# ATSAML22G18A register map
Vendor: Atmel Corporation; Series: SAML22; File version: A
CPU: CM0+ r0p1, little endian, MPU, no FPU, VTOR, 2 interrupt priority bits
Registers are 32-bit, read-write, reset 0x0 unless marked. A register's access mark holds for its fields unless they carry their own. Offsets are from the block's base; [hi:lo] are bit positions; {n}, {i} and the like mark numbered series; 'fields as' and 'values as' point back to an identical list.

## SLCD — Segment Liquid Crystal Display Controller
Base 0x42003C00; register names take the prefix SLCD_
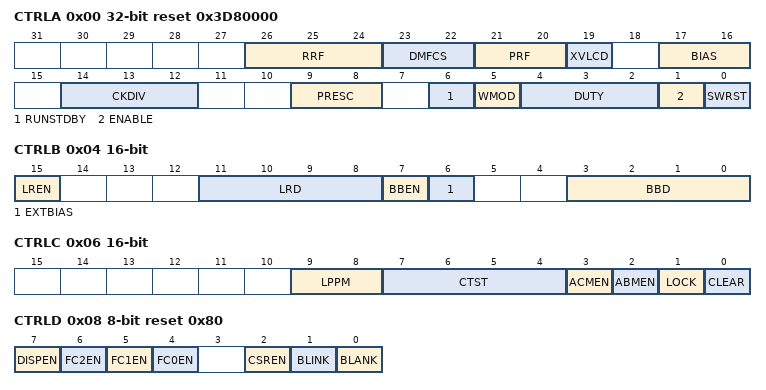
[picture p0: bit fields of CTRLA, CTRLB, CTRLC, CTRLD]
0x00 CTRLA reset 0x3D80000 — Control A
  [26:24] RRF — Reference Refresh Frequency
    0=RR2000 (2kHz); 1=RR1000 (1kHz); 2=RR500 (500Hz); 3=RR250 (250Hz); 4=RR125 (125Hz); 5=RR62 (62.5Hz)
  [23:22] DMFCS — Display Memory Update Frame Counter Selection
    0=FC0 (Frame Counter 0); 1=FC1 (Frame Counter 1); 2=FC2 (Frame Counter 2); 3=NFC (Frame Counter event to DMU is forced to 0)
  [21:20] PRF — Power Refresh Frequency
    0=PR2000 (2kHz); 1=PR1000 (1kHz); 2=PR500 (500Hz); 3=PR250 (250Hz)
  [19] XVLCD — External VLCD
  [17:16] BIAS — Bias Setting
    0=STATIC; 1=HALF (1/2 bias); 2=THIRD (1/3 bias); 3=FOURTH (1/4 bias)
  [14:12] CKDIV — Clock Divider
  [9:8] PRESC — Clock Prescaler
    0=16; 1=32; 2=64; 3=128
  [6] RUNSTDBY — Run in Standby
  [5] WMOD — Waveform Mode
    0=LP (Low Power Waveform Mode); 1=STD (Standard Waveform Mode)
  [4:2] DUTY — Duty Ratio
    0=STATIC (Static duty); 1=HALF (1/2 duty); 2=THIRD (1/3 duty); 3=FOURTH (1/4 duty); 4=SIXTH (1/6 duty); 5=EIGHT (1/8 duty)
  [1] ENABLE
  [0] SWRST — Software Reset
0x04 CTRLB 16-bit — Control B
  [15] LREN — Low Resistance Enable
  [11:8] LRD — Low Resistance Enable Duration
  [7] BBEN — Bias Buffer Enable
  [6] EXTBIAS — External Bias Capacitor
  [3:0] BBD — Bias Buffer Enable Duration
0x06 CTRLC 16-bit — Control C
  [9:8] LPPM — LCD Power Macro Power mode
    0=AUTO (LCD power automatically select regualation mode or pump mode); 1=STEPUP (LCD power use step-up pump loop only); 2=STEPDOWN (LCD power use step-down drop-out regulation loop only)
  [7:4] CTST — Contrast Adjustment
  [3] ACMEN — Automated Character Mapping Enable
  [2] ABMEN — Automated Bit Mapping Enable
  [1] LOCK — Lock Shadow Memory
  [0] CLEAR — Clear Display Memory
0x08 CTRLD 8-bit reset 0x80 — Control D
  [7] DISPEN — Display enable
  [6] FC2EN — Frame Counter 2 Enable
  [5] FC1EN — Frame Counter 1 Enable
  [4] FC0EN — Frame Counter 0 Enable
  [2] CSREN — Circular Shift Register Enable
  [1] BLINK — Blinking Enable
  [0] BLANK — Blank LCD
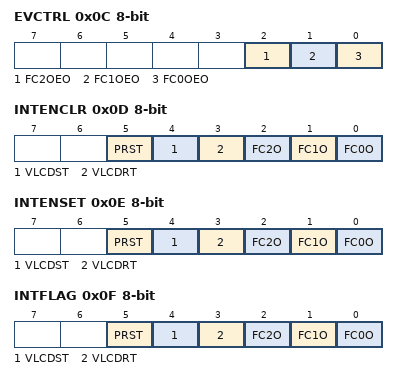
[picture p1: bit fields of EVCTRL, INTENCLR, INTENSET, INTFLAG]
0x0C EVCTRL 8-bit — Event Control
  [2] FC2OEO — Frame Counter 2 Overflow Event Output Enable
  [1] FC1OEO — Frame Counter 1 Overflow Event Output Enable
  [0] FC0OEO — Frame Counter 0 Overflow Event Output Enable
0x0D INTENCLR 8-bit — Interrupt Enable Clear
  [5] PRST — Pump Run Status Toggle Interrupt Disable
  [4] VLCDST — VLCD Status Toggle Interrupt Disable
  [3] VLCDRT — VLCD Ready Toggle Interrupt Disable
  [2] FC2O — Frame Counter 2 Overflow Interrupt Disable
  [1] FC1O — Frame Counter 1 Overflow Interrupt Disable
  [0] FC0O — Frame Counter 0 Overflow Interrupt Disable
0x0E INTENSET 8-bit — Interrupt Enable Set
  [5] PRST — Pump Run Status Toggle Interrupt Enable
  [4] VLCDST — VLCD Status Toggle Interrupt Enable
  [3] VLCDRT — VLCD Ready Toggle Interrupt Enable
  [2] FC2O — Frame Counter 2 Overflow Interrupt Enable
  [1] FC1O — Frame Counter 1 Overflow Interrupt Enable
  [0] FC0O — Frame Counter 0 Overflow Interrupt Enable
0x0F INTFLAG 8-bit — Interrupt Flag Status and Clear
  [5] PRST — Pump Run Status Toggle
  [4] VLCDST — VLCD Status Toggle
  [3] VLCDRT — VLCD Ready Toggle
  [2] FC2O — Frame Counter 2 Overflow
  [1] FC1O — Frame Counter 1 Overflow
  [0] FC0O — Frame Counter 0 Overflow
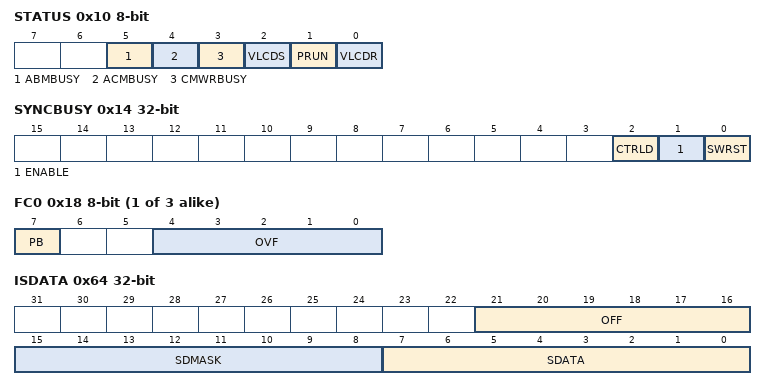
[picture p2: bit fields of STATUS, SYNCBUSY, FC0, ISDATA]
0x10 STATUS 8-bit ro
  [5] ABMBUSY — ABM state machine busy
  [4] ACMBUSY — ACM state machine busy
  [3] CMWRBUSY — Character mapping write busy
  [2] VLCDS — VLCD Status
  [1] PRUN — LCD Charge Pump is Running
  [0] VLCDR — VLCD Ready
0x14 SYNCBUSY ro — Synchronization Busy
  [2] CTRLD — Control D
  [1] ENABLE
  [0] SWRST — Software Reset
{0x18+i} FC{i} 8-bit (i=0..2) — Frame Counter {i} Configuration
  [7] PB — Prescaler Bypass
  [4:0] OVF — Frame Counter Overflow Value
0x1C LPENL — LCD Pin Enable Low
  [31:0] LPEN — LCD Pin Enable
0x20 LPENH — LCD Pin Enable High
  [19:0] LPEN — LCD Pin Enable
{0x24+8i} SDATAL{i} (i=0..7) — Segments Data Low for COM{i} Line
  [31:0] SDATA — Segments Data
{0x28+8i} SDATAH{i} (i=0..3) — Segments Data High for COM{i} Line
  [11:0] SDATA — Segments Data
0x48 SDATAH4 — Segments Data High for COM4 Line
  [9:0] SDATA — Segments Data
0x50 SDATAH5 — Segments Data High for COM5 Line
  [9:0] SDATA — Segments Data
0x58 SDATAH6 — Segments Data High for COM6 Line
  [7:0] SDATA — Segments Data
0x60 SDATAH7 — Segments Data High for COM7 Line
  [7:0] SDATA — Segments Data
0x64 ISDATA wo — Indirect Segments Data Access
  [21:16] OFF — Byte Offset
  [15:8] SDMASK — Segments Data Mask
  [7:0] SDATA — Segments Data
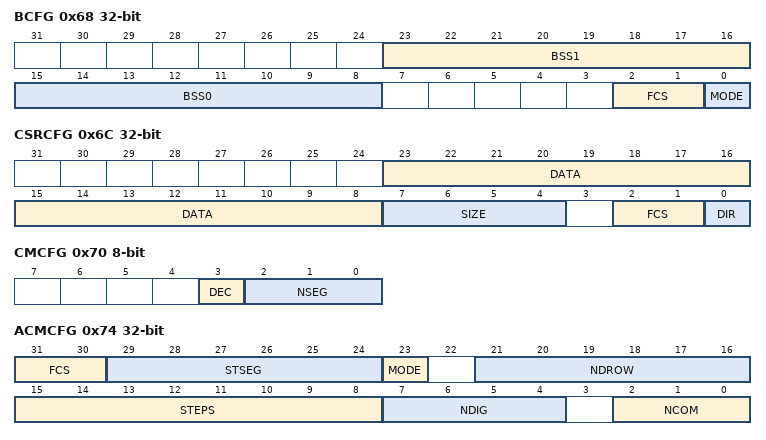
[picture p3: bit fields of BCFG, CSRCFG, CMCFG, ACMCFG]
0x68 BCFG — Blink Configuration
  [23:16] BSS1 — Blink Segment Selection 1
  [15:8] BSS0 — Blink Segment Selection 0
  [2:1] FCS — Frame Counter Selection
    0=FC0 (Frame Counter 0); 1=FC1 (Frame Counter 1); 2=FC2 (Frame Counter 2)
  [0] MODE — Blinking Mode
    0=BLINKALL (Blink all segments); 1=BLINKSEL (Blink selected segments)
0x6C CSRCFG — Circular Shift Register Configuration
  [23:8] DATA — Circular Shift Register Value
  [7:4] SIZE — Circular Shift Register Size
  [2:1] FCS — Frame Counter Selection
    values as BCFG.FCS
  [0] DIR — Direction
0x70 CMCFG 8-bit — Character Mapping Configuration
  [3] DEC — Decrement SEG Line Index
  [2:0] NSEG — Number of SEG lines
0x74 ACMCFG — Automated Character Mapping Configuration
  [31:30] FCS — Frame Counter Selection
    values as BCFG.FCS
  [29:24] STSEG — Start SEG Line
  [23] MODE
    0=SEQ (Sequential Display Mode); 1=SCROLL (Scrolling Display Mode)
  [21:16] NDROW — Number of Digit per Row
  [15:8] STEPS — Scrolling Steps
  [7:4] NDIG — Number of Digit
  [2:0] NCOM — COM Lines per Row
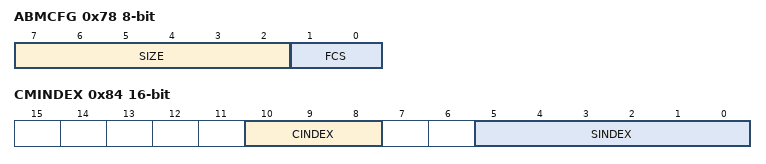
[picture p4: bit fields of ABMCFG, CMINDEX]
0x78 ABMCFG 8-bit — Automated Bit Mapping Configuration
  [7:2] SIZE
  [1:0] FCS — Frame Counter Selection
    values as BCFG.FCS
0x7C CMDATA wo — Character Mapping Segments Data
  [23:0] SDATA — Segments Data
0x80 CMDMASK — Character Mapping Segments Data Mask
  [23:0] SDMASK — Segments Data Mask
0x84 CMINDEX 16-bit — Character Mapping SEG/COM Index
  [10:8] CINDEX — COM Line Index
  [5:0] SINDEX — SEG Line Index
